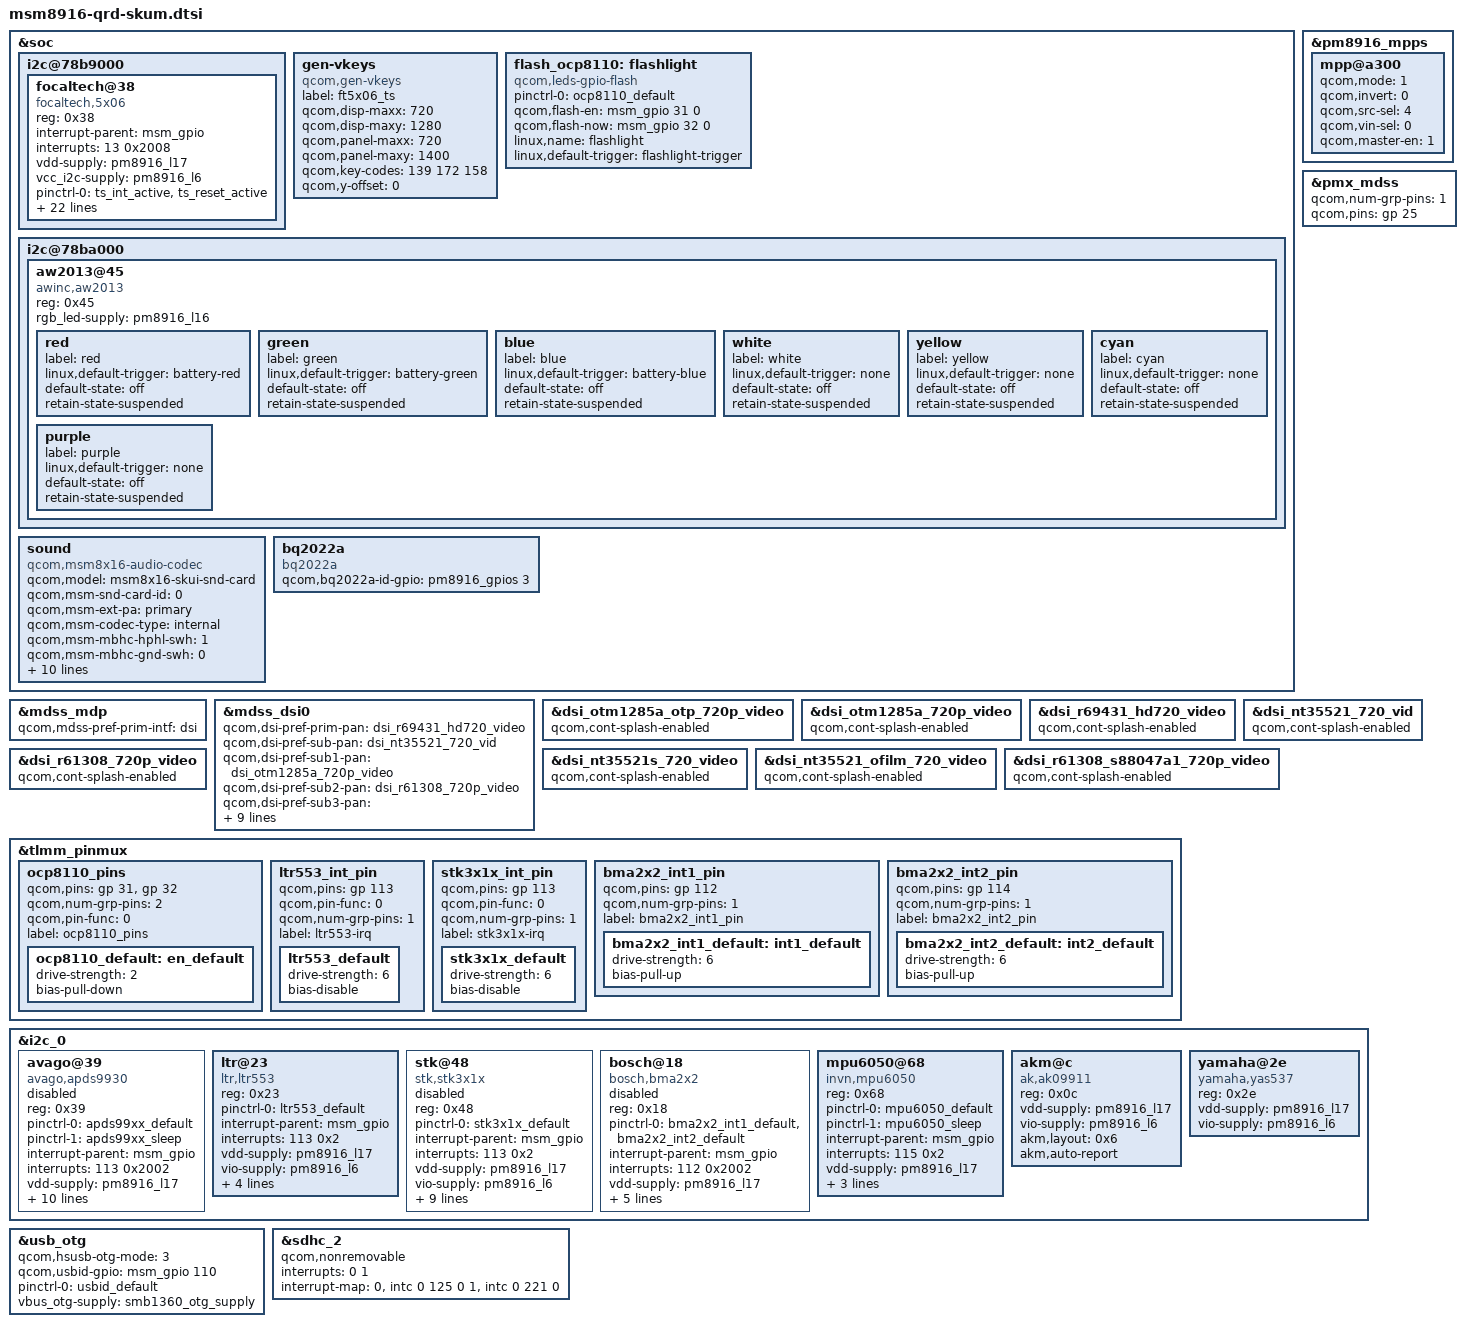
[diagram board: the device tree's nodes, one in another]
/* Copyright (c) 2014, The Linux Foundation. All rights reserved.
 * Copyright (C) 2015 XiaoMi, Inc.
 *
 * This program is free software; you can redistribute it and/or modify
 * it under the terms of the GNU General Public License version 2 and
 * only version 2 as published by the Free Software Foundation.
 *
 * This program is distributed in the hope that it will be useful,
 * but WITHOUT ANY WARRANTY; without even the implied warranty of
 * MERCHANTABILITY or FITNESS FOR A PARTICULAR PURPOSE.  See the
 * GNU General Public License for more details.
 */

#include "msm8916-qrd.dtsi"
#include "dsi-panel-r69431-hd720-video.dtsi"
#include "dsi-panel-nt35521-720p-video.dtsi"
#include "dsi-panel-nt35521s-720p-video.dtsi"
#include "dsi-panel-nt35521-ofilm-720p-video.dtsi"
#include "dsi-panel-otm1285a-720p-video.dtsi"
#include "dsi-panel-r61308-720p-video.dtsi"
#include "dsi-panel-otm1285a-otp-720p-video.dtsi"
#include "dsi-panel-r61308-s88047a1-720p-video.dtsi"
#include "msm8916-camera-sensor-qrd-skum.dtsi"

&soc {
	i2c@78b9000 {
		focaltech@38 {
			compatible = "focaltech,5x06";
			reg = <0x38>;
			interrupt-parent = <&msm_gpio>;
			interrupts = <13 0x2008>;
			vdd-supply = <&pm8916_l17>;
			vcc_i2c-supply = <&pm8916_l6>;

			pinctrl-names = "pmx_ts_active","pmx_ts_suspend";
			pinctrl-0 = <&ts_int_active &ts_reset_active>;
			pinctrl-1 = <&ts_int_suspend &ts_reset_suspend>;
			focaltech,name = "ft6436";
			focaltech,family-id = <0x36>;
			focaltech,reset-gpio = <&msm_gpio 12 0x0>;
			focaltech,irq-gpio = <&msm_gpio 13 0x2008>;
			focaltech,display-coords = <0 0 720 1280>;
			focaltech,panel-coords = <0 0 720 1280>;
			focaltech,button-map= <139 102 158>;
			focaltech,no-force-update;
			focaltech,i2c-pull-up;
			focaltech,group-id = <1>;
			focaltech,hard-reset-delay-ms = <20>;
			focaltech,soft-reset-delay-ms = <200>;
			focaltech,num-max-touches = <10>;
			focaltech,fw-delay-aa-ms = <30>;
			focaltech,fw-delay-55-ms = <30>;
			focaltech,fw-upgrade-id1 = <0x79>;
			focaltech,fw-upgrade-id2 = <0x18>;
			focaltech,fw-delay-readid-ms = <10>;
			focaltech,fw-delay-era-flsh-ms = <2000>;
			focaltech,fw-auto-cal;
			focaltech,ignore-id-check;
		};
	};

	gen-vkeys {
		compatible = "qcom,gen-vkeys";
		label = "ft5x06_ts";
		qcom,disp-maxx = <720>;
		qcom,disp-maxy = <1280>;
		qcom,panel-maxx = <720>;
		qcom,panel-maxy = <1400>;
		qcom,key-codes = <139 172 158>;
		qcom,y-offset = <0>;
	};

	flash_ocp8110:flashlight {
		compatible = "qcom,leds-gpio-flash";
		status = "okay";
		pinctrl-names = "ocp8110_default";
		pinctrl-0 = <&ocp8110_default>;
		qcom,flash-en = <&msm_gpio 31 0>;
		qcom,flash-now = <&msm_gpio 32 0>;
		linux,name = "flashlight";
		linux,default-trigger = "flashlight-trigger";
	};

	i2c@78ba000 {
	aw2013@45 {
		compatible = "awinc,aw2013";
		reg = <0x45>;
		rgb_led-supply = <&pm8916_l16>;

		red {
			label = "red";
			linux,default-trigger = "battery-red";
			default-state = "off";
			retain-state-suspended;
		};

		green {
			label = "green";
			linux,default-trigger = "battery-green";
			default-state = "off";
			retain-state-suspended;
		};

		blue {
			label = "blue";
			linux,default-trigger = "battery-blue";
			default-state = "off";
			retain-state-suspended;
		};

		white {
			label = "white";
			linux,default-trigger = "none";
			default-state = "off";
			retain-state-suspended;
		};

		yellow {
			label = "yellow";
			linux,default-trigger = "none";
			default-state = "off";
			retain-state-suspended;
		};

		cyan {
			label = "cyan";
			linux,default-trigger = "none";
			default-state = "off";
			retain-state-suspended;
		};
		purple {
			label = "purple";
			linux,default-trigger = "none";
			default-state = "off";
			retain-state-suspended;
		};
	};
};

	sound {
		compatible = "qcom,msm8x16-audio-codec";
		qcom,model = "msm8x16-skui-snd-card";
		qcom,msm-snd-card-id = <0>;
		qcom,msm-ext-pa = "primary";
		qcom,msm-codec-type = "internal";
		qcom,msm-mbhc-hphl-swh = <1>;
		qcom,msm-mbhc-gnd-swh = <0>;
		qcom,msm-hs-micbias-type = "internal";
		qcom,audio-routing =
			"RX_BIAS", "MCLK",
			"SPK_RX_BIAS", "MCLK",
			"INT_LDO_H", "MCLK",
			"MIC BIAS External", "Handset Mic",
			"MIC BIAS Internal2", "Headset Mic",
			"MIC BIAS External", "Secondary Mic",
			"AMIC1", "MIC BIAS External",
			"AMIC2", "MIC BIAS Internal2",
			"AMIC3", "MIC BIAS External";
		pinctrl-names = "cdc_lines_act",
				"cdc_lines_sus";
		pinctrl-0 = <&cdc_pdm_lines_act>;
		pinctrl-1 = <&cdc_pdm_lines_sus>;
	};

	bq2022a {
		compatible = "bq2022a";
		qcom,bq2022a-id-gpio = <&pm8916_gpios 3 0>;
		status= "okay";
	};
};

&pm8916_mpps {
	mpp@a300 {

		qcom,mode = <1>;
		qcom,invert = <0>;
		qcom,src-sel = <4>;
		qcom,vin-sel = <0>;
		qcom,master-en = <1>;
	};
};

&mdss_mdp {
	qcom,mdss-pref-prim-intf = "dsi";
};

&pmx_mdss {
	qcom,num-grp-pins = <1>;
	qcom,pins = <&gp 25>;
};

&mdss_dsi0 {
	qcom,dsi-pref-prim-pan = <&dsi_r69431_hd720_video>;
	qcom,dsi-pref-sub-pan = <&dsi_nt35521_720_vid>;
	qcom,dsi-pref-sub1-pan = <&dsi_otm1285a_720p_video>;
	qcom,dsi-pref-sub2-pan = <&dsi_r61308_720p_video>;
	qcom,dsi-pref-sub3-pan = <&dsi_otm1285a_otp_720p_video>;
	qcom,dsi-pref-sub4-pan = <&dsi_r61308_s88047a1_720p_video>;
	qcom,dsi-pref-sub5-pan = <&dsi_nt35521s_720_video>;
	qcom,dsi-pref-sub6-pan = <&dsi_nt35521_ofilm_720_video>;
	pinctrl-names = "mdss_default", "mdss_sleep";
	pinctrl-0 = <&mdss_dsi_active>;
	pinctrl-1 = <&mdss_dsi_suspend>;
	qcom,platform-reset-gpio = <&msm_gpio 25 0>;
};

&dsi_otm1285a_otp_720p_video {
	qcom,cont-splash-enabled;
};

&dsi_otm1285a_720p_video {
	qcom,cont-splash-enabled;
};

&dsi_r69431_hd720_video {
	qcom,cont-splash-enabled;
};

&dsi_nt35521_720_vid {
	qcom,cont-splash-enabled;
};

&dsi_nt35521s_720_video {
	qcom,cont-splash-enabled;
};

&dsi_nt35521_ofilm_720_video {
	qcom,cont-splash-enabled;
};

&dsi_r61308_720p_video {
	qcom,cont-splash-enabled;
};

&dsi_r61308_s88047a1_720p_video {
	qcom,cont-splash-enabled;
};

&tlmm_pinmux {
	ocp8110_pins {
		qcom,pins = <&gp 31>, <&gp 32>;
		qcom,num-grp-pins = <2>;
		qcom,pin-func = <0>;
		label = "ocp8110_pins";
		ocp8110_default: en_default {
			  drive-strength = <2>;
			  bias-pull-down;
		};
	};

	ltr553_int_pin {
		qcom,pins = <&gp 113>;
		qcom,pin-func = <0>;
		qcom,num-grp-pins = <1>;
		label = "ltr553-irq";
		ltr553_default: ltr553_default {
		drive-strength = <6>;
		bias-disable;
		};
	};
	stk3x1x_int_pin {
		qcom,pins = <&gp 113>;
		qcom,pin-func = <0>;
		qcom,num-grp-pins = <1>;
		label = "stk3x1x-irq";
		stk3x1x_default: stk3x1x_default {
		drive-strength = <6>;
		bias-disable;
		};
	};

	bma2x2_int1_pin {
		qcom,pins = <&gp 112>;
		qcom,num-grp-pins = <1>;
		label = "bma2x2_int1_pin";
		bma2x2_int1_default: int1_default {
			  drive-strength = <6>;
			  bias-pull-up;
		};
	};

	bma2x2_int2_pin {
		qcom,pins = <&gp 114>;
		qcom,num-grp-pins = <1>;
		label = "bma2x2_int2_pin";
		bma2x2_int2_default: int2_default {
			  drive-strength = <6>;
			  bias-pull-up;
		};
	};
};

&i2c_0 {
	avago@39 {
		compatible = "avago,apds9930";
		status = "disabled";
		reg = <0x39>;
		pinctrl-names = "default","sleep";
		pinctrl-0 = <&apds99xx_default>;
		pinctrl-1 = <&apds99xx_sleep>;
		interrupt-parent = <&msm_gpio>;
		interrupts = <113 0x2002>;
		vdd-supply = <&pm8916_l17>;
		vio-supply = <&pm8916_l6>;
		avago,irq-gpio = <&msm_gpio 113 0x2002>;
		avago,ps-threshold = <600>;
		avago,ps-hysteresis-threshold = <500>;
		avago,ps-pulse = <8>;
		avago,ps-pgain = <0>;
		avago,als-B = <223>;
		avago,als-C = <70>;
		avago,als-D = <142>;
		avago,ga-value = <48>;
	};

	ltr@23 {
		compatible = "ltr,ltr553";
		reg = <0x23>;
		pinctrl-names = "default";
		pinctrl-0 = <&ltr553_default>;
		interrupt-parent = <&msm_gpio>;
		interrupts = <113 0x2>;
		vdd-supply = <&pm8916_l17>;
		vio-supply = <&pm8916_l6>;
		ltr,irq-gpio = <&msm_gpio 113 0x2>;
		ltr,ps-threshold = <250>;
		ltr,ps-hysteresis-threshold = <150>;
		ltr,als-polling-time = <200>;
		};

	stk@48 {
			compatible = "stk,stk3x1x";
			status = "disabled";
			reg = <0x48>;
			pinctrl-names = "default";
			pinctrl-0 = <&stk3x1x_default>;
			interrupt-parent = <&msm_gpio>;
			interrupts = <113 0x2>;
			vdd-supply = <&pm8916_l17>;
			vio-supply = <&pm8916_l6>;
			stk,irq-gpio = <&msm_gpio 113 0x02>;
			stk,state-reg = <0x00>;
			stk,psctrl-reg = <0x31>;
			stk,alsctrl-reg = <0x39>;
			stk,ledctrl-reg = <0xFF>;
			stk,wait-reg = <0x07>;
			stk,ps-thd-h = <1700>;
			stk,ps-thd-l = <1500>;
			stk,transmittance = <500>;
	};
	bosch@18 {
		compatible = "bosch,bma2x2";
		status = "disabled";
		reg = <0x18>;
		pinctrl-names = "default";
		pinctrl-0 = <&bma2x2_int1_default &bma2x2_int2_default>;
		interrupt-parent = <&msm_gpio>;
		interrupts = <112 0x2002>;
		vdd-supply = <&pm8916_l17>;
		vio-supply = <&pm8916_l6>;
		bosch,init-interval = <200>;
		bosch,place = <2>;
		bosch,gpio-int1 = <&msm_gpio 112 0x2002>;
		bosch,gpio-int2 = <&msm_gpio 114 0x2002>;
	};

	mpu6050@68 {
		compatible = "invn,mpu6050";
		reg = <0x68>;
		pinctrl-names = "mpu_default","mpu_sleep";
		pinctrl-0 = <&mpu6050_default>;
		pinctrl-1 = <&mpu6050_sleep>;
		interrupt-parent = <&msm_gpio>;
		interrupts = <115 0x2>;
		vdd-supply = <&pm8916_l17>;
		vi2c-supply = <&pm8916_l6>;
		invn,gpio-int = <&msm_gpio 115 0x2>;
		invn,place = "Portrait Up Back Side";
	};

	akm@c {
		compatible = "ak,ak09911";
		reg = <0x0c>;
		vdd-supply = <&pm8916_l17>;
		vio-supply = <&pm8916_l6>;
		akm,layout = <0x6>;
		akm,auto-report;
	};

	yamaha@2e {
		compatible = "yamaha,yas537";
		reg = <0x2e>;
		vdd-supply = <&pm8916_l17>;
		vio-supply = <&pm8916_l6>;
	};
};

&usb_otg {
	qcom,hsusb-otg-mode = <3>;
	qcom,usbid-gpio = <&msm_gpio 110 0>;
	pinctrl-names = "default";
	pinctrl-0 = <&usbid_default>;
	vbus_otg-supply = <&smb1360_otg_supply>;
};

&sdhc_2 {
	qcom,nonremovable;

	interrupts = <0 1>;
	interrupt-map = <0 &intc 0 125 0
		1 &intc 0 221 0>;
	interrupt-names = "hc_irq", "pwr_irq";
	/delete-property/ cd-gpios;
};

